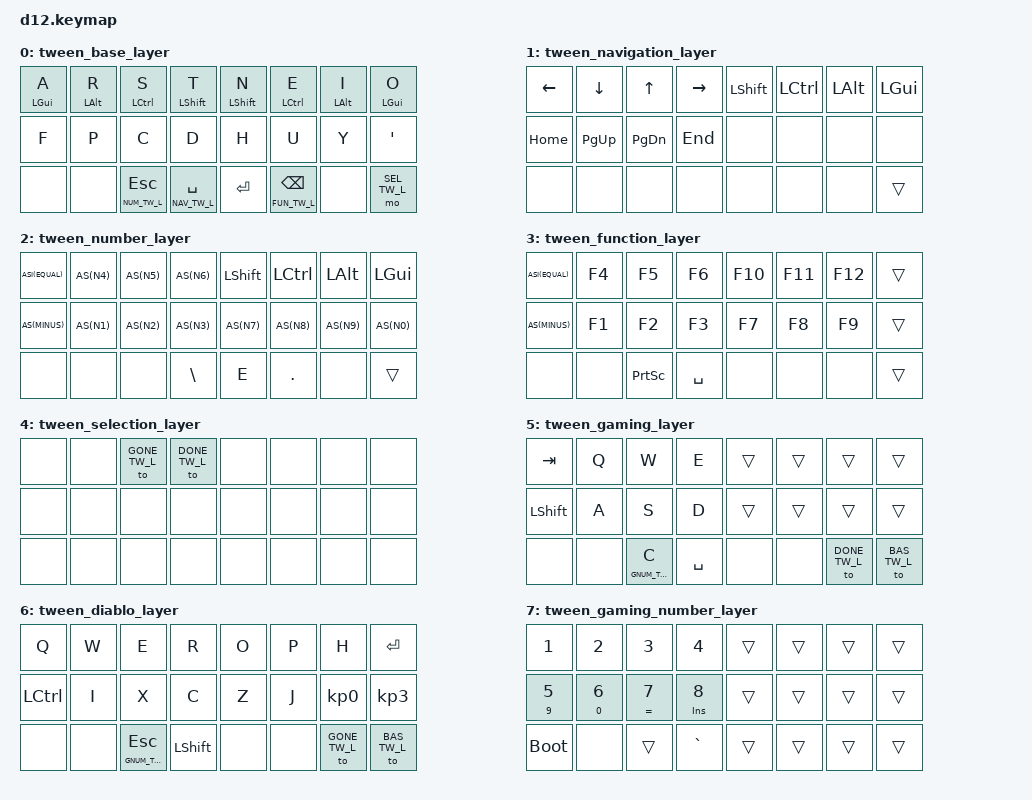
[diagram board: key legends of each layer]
/*
 * Copyright (c) 2022 The ZMK Contributors
 *
 * SPDX-License-Identifier: MIT
 */

#include <behaviors.dtsi>
#include <dt-bindings/zmk/keys.h>

#define AS(keycode) &as LS(keycode) keycode     // Autoshift Macro
#define ASI(keycode) &as keycode LS(keycode)     // Autoshift Macro inverted
#define BAS_TW_L  0
#define NAV_TW_L  1
#define NUM_TW_L  2
#define FUN_TW_L  3
#define SEL_TW_L  4
#define GONE_TW_L 5
#define DONE_TW_L 6
#define GNUM_TW_L 7

#define KEYS_L 0 1 2 3   8  9 10 11
#define KEYS_R 4 5 6 7  12 13 14 15

#define THUMBS 18 19 20 21

// Using layer taps on thumbs, having quick tap as well helps w/ repeating space/backspace
&lt { quick_tap_ms = <200>; };

/*
 *  0  1  2  3    4  5  6  7
 *  8  9 10 11    12 13 14 15
 * 16 17 18 19    20 21 22 23
 */

/ {
    behaviors {
        hml: hrm_left {
            compatible = "zmk,behavior-hold-tap";
            #binding-cells = <2>;
            bindings = <&kp>, <&kp>;
            flavor = "balanced";
            tapping-term-ms = <200>;
            quick-tap-ms = <150>;
            hold-trigger-key-positions = <KEYS_R THUMBS>;
            hold-trigger-on-release;
        };
        hmr: hrm_right {
            compatible = "zmk,behavior-hold-tap";
            #binding-cells = <2>;
            bindings = <&kp>, <&kp>;
            flavor = "balanced";
            tapping-term-ms = <200>;
            quick-tap-ms = <150>;
            hold-trigger-key-positions = <KEYS_L THUMBS>;
            hold-trigger-on-release;
        };
        as: auto_shift {
            compatible = "zmk,behavior-hold-tap";
            #binding-cells = <2>;
            bindings = <&kp>, <&kp>;
            flavor = "tap-preferred";
            tapping_term_ms = <200>;
            quick_tap_ms = <100>;
        };
        ght: gamers_hold_tap {
            compatible = "zmk,behavior-hold-tap";
            #binding-cells = <2>;
            bindings = <&kp>, <&kp>;
            flavor = "hold-preferred";
            tapping_term_ms = <150>;
        };
    };
    keymap {
        compatible = "zmk,keymap";

        tween_base_layer {
            bindings = <
                &hml LGUI A &hml LALT R &hml LCTRL S &hml LSHFT T       &hmr LSHFT N   &hmr LCTRL E   &hmr LALT I   &hmr LGUI O
                 &kp      F  &kp      P &kp        C        &kp D              &kp H          &kp U         &kp Y         &kp QUOT
                &none       &none &lt NUM_TW_L ESC &lt NAV_TW_L SPACE     &kp RET &lt FUN_TW_L BKSP   &none         &mo SEL_TW_L
                >;
        };

        tween_navigation_layer {
            bindings = <
                 &kp LEFT       &kp DOWN       &kp UP       &kp RIGHT      &kp LSHFT &kp LCTRL &kp LALT &kp LGUI
                 &kp HOME  &kp PG_UP &kp PG_DN &kp END &none &none &none &none
                &none &none &none &none &none &none &none &trans
                >;
        };

        tween_number_layer {
            bindings = <
                ASI(EQUAL) AS(N4) AS(N5) AS(N6) &kp LSHFT &kp LCTRL &kp LALT &kp LGUI
                 AS(MINUS) AS(N1) AS(N2) AS(N3)  AS(N7)    AS(N8)    AS(N9)   AS(N0)
                &none &none &none &kp BACKSLASH &kp E &kp DOT &none &trans
                >;
        };

        tween_function_layer {
            bindings = <
                ASI(EQUAL) &kp F4 &kp F5 &kp F6 &kp F10 &kp F11 &kp F12 &trans
                 AS(MINUS) &kp F1 &kp F2 &kp F3 &kp F7  &kp F8  &kp F9  &trans
                &none &none &kp PSCRN &kp SPACE &none &none &none &trans
                >;
        };

        tween_selection_layer {
            bindings = <
                &none &none &to GONE_TW_L  &to DONE_TW_L  &none  &none &none &none
                &none &none &none &none &none &none &none &none
                &none &none &none &none &none &none &none &none
                >;
        };

        tween_gaming_layer {
            bindings = <
                &kp TAB &kp Q &kp W &kp E &trans &trans &trans &trans
                &kp LSHFT &kp A &kp S &kp D &trans &trans &trans &trans
                &none &none &lt GNUM_TW_L C &kp SPACE &none &none &to DONE_TW_L &to BAS_TW_L
                >;
        };

        tween_diablo_layer {
            bindings = <
                &kp Q &kp W &kp E &kp R &kp O &kp P &kp H &kp RET
                &kp LCTRL &kp I &kp X &kp C &kp Z &kp J &kp KP_N0 &kp KP_N3
                &none &none &lt GNUM_TW_L ESC &kp LSHFT &none &none &to GONE_TW_L &to BAS_TW_L
                >;
            // IWC
        };

        tween_gaming_number_layer {
            bindings = <
                &kp N1 &kp N2 &kp N3 &kp N4                     &trans &trans &trans &trans
                &ght N9 N5 &ght N0 N6 &ght EQUAL N7 &ght INS N8 &trans &trans &trans &trans
                &bootloader &none &trans &kp GRAVE &trans &trans &trans &trans
                >;
        };

    };

 /*
 *  0  1  2  3    4  5  6  7
 *  8  9 10 11    12 13 14 15
 * 16 17 18 19    20 21 22 23
 */

    combos {
        compatible = "zmk,combos";

        combo_tw_w         { timeout-ms = <50>; key-positions = <0 1>; bindings = <&kp W>; layers = <BAS_TW_L>; };
        combo_tw_g         { timeout-ms = <50>; key-positions = <1 2>; bindings = <&kp G>; layers = <BAS_TW_L GONE_TW_L>; };
        combo_tw_b         { timeout-ms = <50>; key-positions = <2 3>; bindings = <&kp B>; layers = <BAS_TW_L>; };
        combo_tw_j         { timeout-ms = <50>; key-positions = <4 5>; bindings = <&kp J>; layers = <BAS_TW_L>; };
        combo_tw_l         { timeout-ms = <50>; key-positions = <5 6>; bindings = <&kp L>; layers = <BAS_TW_L>; };
        combo_tw_m         { timeout-ms = <50>; key-positions = <6 7>; bindings = <&kp M>; layers = <BAS_TW_L>; };

        combo_tw_z         { timeout-ms = <50>; key-positions = <9 10>; bindings = <&kp Z>; layers = <BAS_TW_L GONE_TW_L>; };
        combo_tw_x         { timeout-ms = <50>; key-positions = <10 11>; bindings = <&kp X>; layers = <BAS_TW_L GONE_TW_L>; };
        combo_tw_comma     { timeout-ms = <50>; key-positions = <12 13>; bindings = <&kp COMMA>; layers = <BAS_TW_L>; };
        combo_tw_dot       { timeout-ms = <50>; key-positions = <13 14>; bindings = <&kp DOT>; layers = <BAS_TW_L>; };

        combo_tw_angle_l   { timeout-ms = <50>; key-positions = <0 8>; bindings = <&kp LT>; layers = <BAS_TW_L>; };
        combo_tw_brace_l   { timeout-ms = <50>; key-positions = <1 9>; bindings = <&kp LBRC>; layers = <BAS_TW_L>; };
        combo_tw_bracket_l { timeout-ms = <50>; key-positions = <2 10>; bindings = <&kp LBKT>; layers = <BAS_TW_L>; };
        combo_tw_paren_l   { timeout-ms = <50>; key-positions = <3 11>; bindings = <&kp LPAR>; layers = <BAS_TW_L>; };
        combo_tw_paren_r   { timeout-ms = <50>; key-positions = <4 12>; bindings = <&kp RPAR>; layers = <BAS_TW_L>; };
        combo_tw_bracket_r { timeout-ms = <50>; key-positions = <5 13>; bindings = <&kp RBKT>; layers = <BAS_TW_L>; };
        combo_tw_brace_r   { timeout-ms = <50>; key-positions = <6 14>; bindings = <&kp RBRC>; layers = <BAS_TW_L>; };
        combo_tw_angle_r   { timeout-ms = <50>; key-positions = <7 15>; bindings = <&kp GT>; layers = <BAS_TW_L>; };

        combo_tw_grave     { timeout-ms = <50>; key-positions = <1 10>; bindings = <&kp GRAVE>; layers = <BAS_TW_L>; };
        combo_tw_v         { timeout-ms = <50>; key-positions = <2 11>; bindings = <&kp V>; layers = <BAS_TW_L GONE_TW_L>; };
        combo_tw_k         { timeout-ms = <50>; key-positions = <5 12>; bindings = <&kp K>; layers = <BAS_TW_L>; };
        combo_tw_slash     { timeout-ms = <50>; key-positions = <6 13>; bindings = <&kp FSLH>; layers = <BAS_TW_L>; };

        combo_tw_q         { timeout-ms = <50>; key-positions = <9 11>; bindings = <&kp Q>; layers = <BAS_TW_L>; };
        combo_tw_tab       { timeout-ms = <50>; key-positions = <1 3>; bindings = <&kp TAB>; layers = <BAS_TW_L>; };
        combo_tw_delete    { timeout-ms = <50>; key-positions = <4 6>; bindings = <&kp DEL>; layers = <BAS_TW_L>; };
        combo_tw_semicolon { timeout-ms = <50>; key-positions = <12 14>; bindings = <&kp SEMI>; layers = <BAS_TW_L>; };

        combo_tw_forw_word { timeout-ms = <50>; key-positions = <4 7>; bindings = <&kp LC(DEL)>; layers = <BAS_TW_L>; };
        combo_tw_capslock  { timeout-ms = <50>; key-positions = <0 7>; bindings = <&kp CAPS>; layers = <BAS_TW_L>; };
        combo_tw_capsword  { timeout-ms = <50>; key-positions = <3 4>; bindings = <&caps_word>; layers = <BAS_TW_L>; };
        combo_tw_back_word { timeout-ms = <50>; key-positions = <0 3>; bindings = <&kp LC(BKSP)>; layers = <BAS_TW_L>; };

        combo_tw_game_esc  { timeout-ms = <50>; key-positions = <0 1>; bindings = <&kp ESC>; layers = <GONE_TW_L>; };
        combo_tw_game_lctl { timeout-ms = <50>; key-positions = <18 19>; bindings = <&kp LCTRL>; layers = <GONE_TW_L>; };
        combo_tw_game_lalt { timeout-ms = <50>; key-positions = <11 19>; bindings = <&kp LALT>; layers = <GONE_TW_L>; };
        combo_tw_game_f    { timeout-ms = <50>; key-positions = <3 11>; bindings = <&kp F>; layers = <GONE_TW_L>; };
        combo_tw_game_r    { timeout-ms = <50>; key-positions = <2 3>; bindings = <&kp R>; layers = <GONE_TW_L>; };
    };

/*
 *  0  1  2  3    4  5  6  7
 *  8  9 10 11    12 13 14 15
 * 16 17 18 19    20 21 22 23
 */


};
